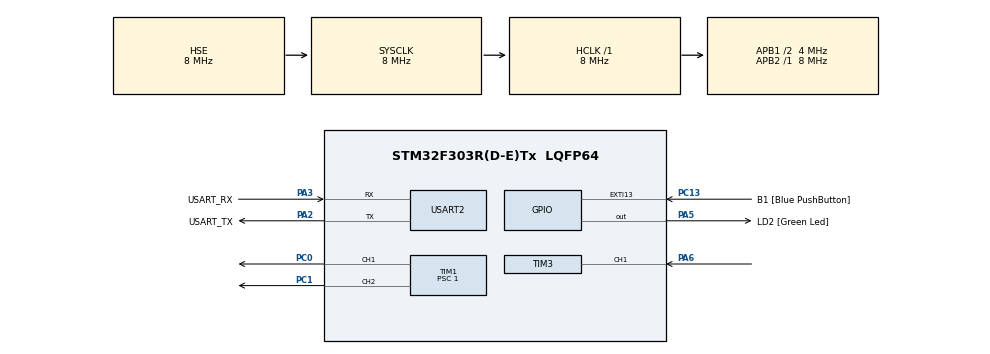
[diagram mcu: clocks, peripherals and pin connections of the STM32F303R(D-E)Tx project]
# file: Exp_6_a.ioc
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Mcu.Family=STM32F3
Mcu.Name=STM32F303R(D-E)Tx
Mcu.Package=LQFP64
NVIC.PriorityGroup=NVIC_PRIORITYGROUP_0
NVIC.TIM1_CC_IRQn=true\:0\:0\:false\:false\:true\:true\:true
NVIC.TIM3_IRQn=true\:0\:0\:false\:false\:true\:true\:true
PA13.GPIO_Label=TMS
PA13.Mode=Serial_Wire
PA13.Signal=SYS_JTMS-SWDIO
PA14.GPIO_Label=TCK
PA14.Mode=Serial_Wire
PA14.Signal=SYS_JTCK-SWCLK
PA2.GPIO_Label=USART_TX
PA2.GPIO_Mode=GPIO_MODE_AF_PP
PA2.GPIO_PuPd=GPIO_NOPULL
PA2.GPIO_Speed=GPIO_SPEED_FREQ_LOW
PA2.Mode=Asynchronous
PA2.Signal=USART2_TX
PA3.GPIO_Label=USART_RX
PA3.GPIO_Mode=GPIO_MODE_AF_PP
PA3.GPIO_PuPd=GPIO_NOPULL
PA3.GPIO_Speed=GPIO_SPEED_FREQ_LOW
PA3.Mode=Asynchronous
PA3.Signal=USART2_RX
PA5.GPIO_Label=LD2 [Green Led]
PA5.GPIO_Mode=GPIO_MODE_OUTPUT_PP
PA5.GPIO_PuPd=GPIO_NOPULL
PA5.GPIO_Speed=GPIO_SPEED_FREQ_LOW
PA5.Signal=GPIO_Output
PA6.Signal=S_TIM3_CH1
PB3.GPIO_Label=SWO
PB3.Signal=SYS_JTDO-TRACESWO
PC0.Signal=S_TIM1_CH1
PC1.Signal=S_TIM1_CH2
PC13.GPIO_Label=B1 [Blue PushButton]
PC13.GPIO_ModeDefaultEXTI=GPIO_MODE_IT_FALLING
PC13.Signal=GPXTI13
PC14-OSC32_IN.Signal=RCC_OSC32_IN
PC15-OSC32_OUT.Signal=RCC_OSC32_OUT
PF0-OSC_IN.Mode=HSE-External-Oscillator
PF0-OSC_IN.Signal=RCC_OSC_IN
PF1-OSC_OUT.Mode=HSE-External-Oscillator
PF1-OSC_OUT.Signal=RCC_OSC_OUT
ProjectManager.HeapSize=0x200
ProjectManager.StackSize=0x400
ProjectManager.TargetToolchain=MDK-ARM V5
RCC.AHBFreq_Value=8000000
RCC.APB1CLKDivider=RCC_HCLK_DIV2
RCC.APB1Freq_Value=4000000
RCC.APB1TimFreq_Value=8000000
RCC.APB2Freq_Value=8000000
RCC.APB2TimFreq_Value=8000000
RCC.CortexFreq_Value=8000000
RCC.HCLKFreq_Value=8000000
RCC.HSE_VALUE=8000000
RCC.HSI_VALUE=8000000
RCC.PLLM=8
RCC.PLLMUL=RCC_PLL_MUL9
RCC.PLLN=336
RCC.PLLP=RCC_PLLP_DIV4
RCC.PLLQ=7
RCC.PLLSourceVirtual=RCC_PLLSOURCE_HSE
RCC.RCC_PLLsource_Clock_Source_FROM_HSE=RCC_HSE_PREDIV_DIV2
RCC.SYSCLKFreq_VALUE=8000000
RCC.SYSCLKSourceVirtual=RCC_SYSCLKSOURCE_HSE
RCC.USBFreq_Value=72000000
SH.S_TIM1_CH1.0=TIM1_CH1,PWM Generation1 CH1
SH.S_TIM1_CH2.0=TIM1_CH2,PWM Generation2 CH2
SH.S_TIM3_CH1.0=TIM3_CH1,TriggerSource_TI1FP1
SH.S_TIM3_CH1.1=TIM3_CH1,Input_Capture1_from_TI1
TIM1.Channel-PWM\ Generation1\ CH1=TIM_CHANNEL_1
TIM1.Channel-PWM\ Generation2\ CH2=TIM_CHANNEL_2
TIM1.Period=16
TIM1.Prescaler=1
TIM3.Channel-Input_Capture1_from_TI1=TIM_CHANNEL_1
TIM3.Period=65000
TIM3.Prescaler=1
USART2.VirtualMode-Asynchronous=VM_ASYNC
VP_TIM1_VS_ClockSourceINT.Mode=Internal
VP_TIM3_VS_ClockSourceINT.Mode=Internal
VP_TIM3_VS_ControllerModeReset.Mode=Reset Mode
board=NUCLEO-F303RE

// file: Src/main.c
/* USER CODE BEGIN Header */
/**
  ******************************************************************************
  * @file           : main.c
  * @brief          : Main program body
  ******************************************************************************
  * @attention
  *
  * <h2><center>&copy; Copyright (c) 2019 STMicroelectronics.
  * All rights reserved.</center></h2>
  *
  * This software component is licensed by ST under BSD 3-Clause license,
  * the "License"; You may not use this file except in compliance with the
  * License. You may obtain a copy of the License at:
  *                        opensource.org/licenses/BSD-3-Clause
  *
  ******************************************************************************
  */
/* USER CODE END Header */

#include "main.h"

TIM_HandleTypeDef htim1;
TIM_HandleTypeDef htim3;

UART_HandleTypeDef huart2;

/* USER CODE BEGIN PV */
uint16_t Capture;
float cntClk,signalFreq;
uint8_t dutyCycle1 = 50,dutyCycle2 = 80, Period, pwmOp; // Duty cycle interms of percentage
/* USER CODE END PV */

void SystemClock_Config(void);
static void MX_GPIO_Init(void);
static void MX_TIM3_Init(void);
static void MX_USART2_UART_Init(void);
static void MX_TIM1_Init(void);

/* USER CODE BEGIN 0 */
void HAL_TIM_IC_CaptureCallback(TIM_HandleTypeDef *htim)
{
  if(htim->Channel == HAL_TIM_ACTIVE_CHANNEL_1)
	{
		Capture = HAL_TIM_ReadCapturedValue(&htim3,TIM_CHANNEL_1);
		cntClk = HAL_RCC_GetPCLK1Freq();
		signalFreq = cntClk/Capture;
	}
}
/* USER CODE END 0 */

int main(void)
{

  /* MCU Configuration--------------------------------------------------------*/

  /* Reset of all peripherals, Initializes the Flash interface and the Systick. */
  HAL_Init();

  /* Configure the system clock */
  SystemClock_Config();

  /* Initialize all configured peripherals */
  MX_GPIO_Init();
  MX_TIM3_Init();
  MX_USART2_UART_Init();
  MX_TIM1_Init();
  /* USER CODE BEGIN 2 */
		HAL_TIM_IC_Start_IT(&htim3,TIM_CHANNEL_1); // Timer is taken in intterupt capture mode
		HAL_TIM_PWM_Start(&htim1,TIM_CHANNEL_1);
		HAL_TIM_PWM_Start(&htim1,TIM_CHANNEL_2);
		Period = htim1.Init.Period+1;

  /* USER CODE END 2 */

  /* Infinite loop */
  while (1)
  {

    /* USER CODE BEGIN 3 */
				TIM1->CCR1=dutyCycle1*Period/100; // 100 is because the dutycycle is defined interms of percentage
		TIM1->CCR2=dutyCycle2*Period/100;
  }
  /* USER CODE END 3 */
}

void SystemClock_Config(void)
{
  RCC_OscInitTypeDef RCC_OscInitStruct = {0};
  RCC_ClkInitTypeDef RCC_ClkInitStruct = {0};
  RCC_PeriphCLKInitTypeDef PeriphClkInit = {0};

  /** Initializes the CPU, AHB and APB busses clocks
  */
  RCC_OscInitStruct.OscillatorType = RCC_OSCILLATORTYPE_HSE;
  RCC_OscInitStruct.HSEState = RCC_HSE_ON;
  RCC_OscInitStruct.HSIState = RCC_HSI_ON;
  RCC_OscInitStruct.PLL.PLLState = RCC_PLL_NONE;
  if (HAL_RCC_OscConfig(&RCC_OscInitStruct) != HAL_OK)
  {
    Error_Handler();
  }
  /** Initializes the CPU, AHB and APB busses clocks
  */
  RCC_ClkInitStruct.ClockType = RCC_CLOCKTYPE_HCLK|RCC_CLOCKTYPE_SYSCLK
                              |RCC_CLOCKTYPE_PCLK1|RCC_CLOCKTYPE_PCLK2;
  RCC_ClkInitStruct.SYSCLKSource = RCC_SYSCLKSOURCE_HSE;
  RCC_ClkInitStruct.AHBCLKDivider = RCC_SYSCLK_DIV1;
  RCC_ClkInitStruct.APB1CLKDivider = RCC_HCLK_DIV2;
  RCC_ClkInitStruct.APB2CLKDivider = RCC_HCLK_DIV1;

  if (HAL_RCC_ClockConfig(&RCC_ClkInitStruct, FLASH_LATENCY_0) != HAL_OK)
  {
    Error_Handler();
  }
  PeriphClkInit.PeriphClockSelection = RCC_PERIPHCLK_USART2|RCC_PERIPHCLK_TIM1
                              |RCC_PERIPHCLK_TIM34;
  PeriphClkInit.Usart2ClockSelection = RCC_USART2CLKSOURCE_PCLK1;
  PeriphClkInit.Tim1ClockSelection = RCC_TIM1CLK_HCLK;
  PeriphClkInit.Tim34ClockSelection = RCC_TIM34CLK_HCLK;
  if (HAL_RCCEx_PeriphCLKConfig(&PeriphClkInit) != HAL_OK)
  {
    Error_Handler();
  }
}

static void MX_TIM1_Init(void)
{

  TIM_ClockConfigTypeDef sClockSourceConfig = {0};
  TIM_MasterConfigTypeDef sMasterConfig = {0};
  TIM_OC_InitTypeDef sConfigOC = {0};
  TIM_BreakDeadTimeConfigTypeDef sBreakDeadTimeConfig = {0};

  htim1.Instance = TIM1;
  htim1.Init.Prescaler = 1;
  htim1.Init.CounterMode = TIM_COUNTERMODE_UP;
  htim1.Init.Period = 3999;
  htim1.Init.ClockDivision = TIM_CLOCKDIVISION_DIV1;
  htim1.Init.RepetitionCounter = 0;
  htim1.Init.AutoReloadPreload = TIM_AUTORELOAD_PRELOAD_DISABLE;
  if (HAL_TIM_Base_Init(&htim1) != HAL_OK)
  {
    Error_Handler();
  }
  sClockSourceConfig.ClockSource = TIM_CLOCKSOURCE_INTERNAL;
  if (HAL_TIM_ConfigClockSource(&htim1, &sClockSourceConfig) != HAL_OK)
  {
    Error_Handler();
  }
  if (HAL_TIM_PWM_Init(&htim1) != HAL_OK)
  {
    Error_Handler();
  }
  sMasterConfig.MasterOutputTrigger = TIM_TRGO_RESET;
  sMasterConfig.MasterOutputTrigger2 = TIM_TRGO2_RESET;
  sMasterConfig.MasterSlaveMode = TIM_MASTERSLAVEMODE_DISABLE;
  if (HAL_TIMEx_MasterConfigSynchronization(&htim1, &sMasterConfig) != HAL_OK)
  {
    Error_Handler();
  }
  sConfigOC.OCMode = TIM_OCMODE_PWM1;
  sConfigOC.Pulse = 0;
  sConfigOC.OCPolarity = TIM_OCPOLARITY_HIGH;
  sConfigOC.OCNPolarity = TIM_OCNPOLARITY_HIGH;
  sConfigOC.OCFastMode = TIM_OCFAST_DISABLE;
  sConfigOC.OCIdleState = TIM_OCIDLESTATE_RESET;
  sConfigOC.OCNIdleState = TIM_OCNIDLESTATE_RESET;
  if (HAL_TIM_PWM_ConfigChannel(&htim1, &sConfigOC, TIM_CHANNEL_1) != HAL_OK)
  {
    Error_Handler();
  }
  if (HAL_TIM_PWM_ConfigChannel(&htim1, &sConfigOC, TIM_CHANNEL_2) != HAL_OK)
  {
    Error_Handler();
  }
  sBreakDeadTimeConfig.OffStateRunMode = TIM_OSSR_DISABLE;
  sBreakDeadTimeConfig.OffStateIDLEMode = TIM_OSSI_DISABLE;
  sBreakDeadTimeConfig.LockLevel = TIM_LOCKLEVEL_OFF;
  sBreakDeadTimeConfig.DeadTime = 0;
  sBreakDeadTimeConfig.BreakState = TIM_BREAK_DISABLE;
  sBreakDeadTimeConfig.BreakPolarity = TIM_BREAKPOLARITY_HIGH;
  sBreakDeadTimeConfig.BreakFilter = 0;
  sBreakDeadTimeConfig.Break2State = TIM_BREAK2_DISABLE;
  sBreakDeadTimeConfig.Break2Polarity = TIM_BREAK2POLARITY_HIGH;
  sBreakDeadTimeConfig.Break2Filter = 0;
  sBreakDeadTimeConfig.AutomaticOutput = TIM_AUTOMATICOUTPUT_DISABLE;
  if (HAL_TIMEx_ConfigBreakDeadTime(&htim1, &sBreakDeadTimeConfig) != HAL_OK)
  {
    Error_Handler();
  }
  HAL_TIM_MspPostInit(&htim1);

}

static void MX_TIM3_Init(void)
{

  TIM_ClockConfigTypeDef sClockSourceConfig = {0};
  TIM_SlaveConfigTypeDef sSlaveConfig = {0};
  TIM_MasterConfigTypeDef sMasterConfig = {0};
  TIM_IC_InitTypeDef sConfigIC = {0};

  htim3.Instance = TIM3;
  htim3.Init.Prescaler = 1;
  htim3.Init.CounterMode = TIM_COUNTERMODE_UP;
  htim3.Init.Period = 65000;
  htim3.Init.ClockDivision = TIM_CLOCKDIVISION_DIV1;
  htim3.Init.AutoReloadPreload = TIM_AUTORELOAD_PRELOAD_DISABLE;
  if (HAL_TIM_Base_Init(&htim3) != HAL_OK)
  {
    Error_Handler();
  }
  sClockSourceConfig.ClockSource = TIM_CLOCKSOURCE_INTERNAL;
  if (HAL_TIM_ConfigClockSource(&htim3, &sClockSourceConfig) != HAL_OK)
  {
    Error_Handler();
  }
  if (HAL_TIM_IC_Init(&htim3) != HAL_OK)
  {
    Error_Handler();
  }
  sSlaveConfig.SlaveMode = TIM_SLAVEMODE_RESET;
  sSlaveConfig.InputTrigger = TIM_TS_TI1FP1;
  sSlaveConfig.TriggerPolarity = TIM_INPUTCHANNELPOLARITY_RISING;
  sSlaveConfig.TriggerFilter = 0;
  if (HAL_TIM_SlaveConfigSynchronization(&htim3, &sSlaveConfig) != HAL_OK)
  {
    Error_Handler();
  }
  sMasterConfig.MasterOutputTrigger = TIM_TRGO_RESET;
  sMasterConfig.MasterSlaveMode = TIM_MASTERSLAVEMODE_DISABLE;
  if (HAL_TIMEx_MasterConfigSynchronization(&htim3, &sMasterConfig) != HAL_OK)
  {
    Error_Handler();
  }
  sConfigIC.ICPolarity = TIM_INPUTCHANNELPOLARITY_RISING;
  sConfigIC.ICSelection = TIM_ICSELECTION_DIRECTTI;
  sConfigIC.ICPrescaler = TIM_ICPSC_DIV1;
  sConfigIC.ICFilter = 0;
  if (HAL_TIM_IC_ConfigChannel(&htim3, &sConfigIC, TIM_CHANNEL_1) != HAL_OK)
  {
    Error_Handler();
  }

}

static void MX_USART2_UART_Init(void)
{

  huart2.Instance = USART2;
  huart2.Init.BaudRate = 38400;
  huart2.Init.WordLength = UART_WORDLENGTH_8B;
  huart2.Init.StopBits = UART_STOPBITS_1;
  huart2.Init.Parity = UART_PARITY_NONE;
  huart2.Init.Mode = UART_MODE_TX_RX;
  huart2.Init.HwFlowCtl = UART_HWCONTROL_NONE;
  huart2.Init.OverSampling = UART_OVERSAMPLING_16;
  huart2.Init.OneBitSampling = UART_ONE_BIT_SAMPLE_DISABLE;
  huart2.AdvancedInit.AdvFeatureInit = UART_ADVFEATURE_NO_INIT;
  if (HAL_UART_Init(&huart2) != HAL_OK)
  {
    Error_Handler();
  }

}

static void MX_GPIO_Init(void)
{
  GPIO_InitTypeDef GPIO_InitStruct = {0};

  /* GPIO Ports Clock Enable */
  __HAL_RCC_GPIOC_CLK_ENABLE();
  __HAL_RCC_GPIOF_CLK_ENABLE();
  __HAL_RCC_GPIOA_CLK_ENABLE();
  __HAL_RCC_GPIOB_CLK_ENABLE();

  /*Configure GPIO pin Output Level */
  HAL_GPIO_WritePin(LD2_GPIO_Port, LD2_Pin, GPIO_PIN_RESET);

  /*Configure GPIO pin : B1_Pin */
  GPIO_InitStruct.Pin = B1_Pin;
  GPIO_InitStruct.Mode = GPIO_MODE_IT_FALLING;
  GPIO_InitStruct.Pull = GPIO_NOPULL;
  HAL_GPIO_Init(B1_GPIO_Port, &GPIO_InitStruct);

  /*Configure GPIO pin : LD2_Pin */
  GPIO_InitStruct.Pin = LD2_Pin;
  GPIO_InitStruct.Mode = GPIO_MODE_OUTPUT_PP;
  GPIO_InitStruct.Pull = GPIO_NOPULL;
  GPIO_InitStruct.Speed = GPIO_SPEED_FREQ_LOW;
  HAL_GPIO_Init(LD2_GPIO_Port, &GPIO_InitStruct);

}

void Error_Handler(void)
{
}

/************************ (C) COPYRIGHT STMicroelectronics *****END OF FILE****/
